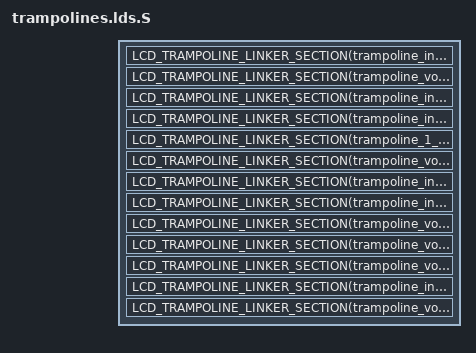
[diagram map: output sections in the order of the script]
#include <liblcd/trampoline_link.h>

SECTIONS
{
	LCD_TRAMPOLINE_LINKER_SECTION(trampoline_int_1_kernel_nullnet_net_device_ndo_init)
	LCD_TRAMPOLINE_LINKER_SECTION(trampoline_void_1_kernel_nullnet_net_device_ndo_uninit)
	LCD_TRAMPOLINE_LINKER_SECTION(trampoline_int_1_kernel_nullnet_sk_buff_ndo_start_xmit_1_kernel_nullnet_net_device_stats)
	LCD_TRAMPOLINE_LINKER_SECTION(trampoline_int_1_kernel_nullnet_net_device_ndo_validate_addr)
	LCD_TRAMPOLINE_LINKER_SECTION(trampoline_1_kernel_nullnet_rtnl_link_stats64_1_kernel_nullnet_net_device_ndo_get_stats64_1_kernel_nullnet_rtnl_link_stats64_ndo_get_stats64)
	LCD_TRAMPOLINE_LINKER_SECTION(trampoline_void_1_kernel_nullnet_net_device_ndo_set_rx_mode)
	LCD_TRAMPOLINE_LINKER_SECTION(trampoline_int_1_kernel_nullnet_net_device_ndo_set_mac_address_1_kernel_nullnet_sockaddr)
	LCD_TRAMPOLINE_LINKER_SECTION(trampoline_int_1_kernel_nullnet_net_device_ndo_change_carrier_bool)
	LCD_TRAMPOLINE_LINKER_SECTION(trampoline_void_1_kernel_nullnet_net_device_get_drvinfo_1_kernel_nullnet_ethtool_drvinfo_get_drvinfo)
	LCD_TRAMPOLINE_LINKER_SECTION(trampoline_void_1_kernel_nullnet_net_device_destructor)
	LCD_TRAMPOLINE_LINKER_SECTION(trampoline_void_1_kernel_nullnet_net_device_setup)
	LCD_TRAMPOLINE_LINKER_SECTION(trampoline_int_1_kernel_nullnet_void_ptr_1_kernel_nullnet_void_ptr)
	LCD_TRAMPOLINE_LINKER_SECTION(trampoline_void_1_kernel_nullnet_net_device_setup_callee_alloc)
}
INSERT AFTER .text

